# RL6842_IP_SVD register map
Vendor: Realtek
Registers are 32-bit, read-write, reset 0x0 unless marked. A register's access mark holds for its fields unless they carry their own. Offsets are from the block's base; [hi:lo] are bit positions; {n}, {i} and the like mark numbered series; <NAME> marks a mode.

## LP_SYS
Base 0x4100C200
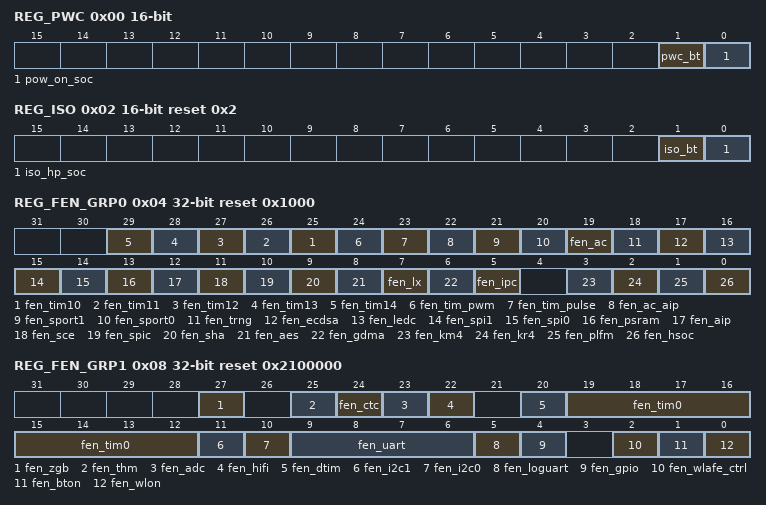
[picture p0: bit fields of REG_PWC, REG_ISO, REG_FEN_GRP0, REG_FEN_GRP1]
0x00 REG_PWC 16-bit
  [1] pwc_bt — This is BT function total power cut control 1: Enable BT power cut 0: Disable
  [0] pow_on_soc — 1:SYS PMC request to enable HP SOC power cut and diable ISO 0: SYS PMC request to disable HP SOC power cut and enable ISO
0x02 REG_ISO 16-bit access per field reset 0x2
  [1] iso_bt rw — 1: isolate signals from PD_LP_BT to other power domain 0: release iso
  [0] iso_hp_soc ro — isolate signals from PD_HP_SOC to other power domain
0x04 REG_FEN_GRP0 reset 0x1000
  [n+15] fen_tim{n} (n=10..14) — 1: enable TIMER {n} function 0: disable
  [24] fen_tim_pwm — 1: enable PWM TIMER function 0: disable
  [23] fen_tim_pulse — 1: enable PULSE TIMER function 0: disable
  [22] fen_ac_aip — 1: enable audio codec analog ip active function, need level shift to 3.3V for audio aip 0: disable
  [21] fen_sport1 — 1: enable SPORT1 function 0: disable
  [20] fen_sport0 — 1: enable SPORT0 function 0: disable
  [19] fen_ac — 1: enable audio codec digital ip active function 0: disable
  [18] fen_trng — 1: enable TRNG function 0: disable
  [17] fen_ecdsa — 1: enable ecdsa function 0: disable
  [16] fen_ledc — 1: enable LEDC function 0: disable
  [15] fen_spi1 — 1: enable SPI1 function 0: disable
  [14] fen_spi0 — 1: enable SPI0 function 0: disable
  [13] fen_psram — 1: enable PSRAM function 0: disable
  [12] fen_aip — AIP control function enable 1: enable 0: disable
  [11] fen_sce — Flash sce function enable 1: enable sce 0: disable
  [10] fen_spic — Flash spic function enable 1: enable flash 0: disable flash
  [9] fen_sha — 1: enable IPSEC SHA function 0: disable
  [8] fen_aes — 1: enable IPSEC AES function 0: disable
  [7] fen_lx — 1: enable LX1 system function 0: disable
  [6] fen_gdma — 1: enable GDMA function 0: disable
  [5] fen_ipc — 1: enable IPC function 0: reset
  [3] fen_km4 — 1: enable KM4 0: reset
  [2] fen_kr4 — 1: enable KR4 0: reset
  [1] fen_plfm — 1: enable platform 0: reset
  [0] fen_hsoc — 1: enable hs soc sytem 0: reset all hs soc sytem , include km4/km0/plfm/hifi
0x08 REG_FEN_GRP1 reset 0x2100000
  [27] fen_zgb — zigbee function enable 1: enable 0: disable
  [25] fen_thm — thermal function enable 1: enable 0: disable
  [24] fen_ctc — captouch function enable 1: enable 0: disable
  [23] fen_adc — lp adc function enable 1: enable 0: disable
  [22] fen_hifi — HIFI core function enable 1: enable 0: disable
  [20] fen_dtim — Debug timer function enable 1: enable 0: disable
  [19:12] fen_tim0 — Basic Timer0-7 function enable 1: enable 0: disable
  [11] fen_i2c1 — I2C1 function enable 1: enable 0: disable
  [10] fen_i2c0 — I2C0 function enable 1: enable 0: disable
  [9:6] fen_uart — Uart function enable (Note uart3 if for BT) 1: enable 0: disable
  [5] fen_loguart — Uartlog function enable 1: enable 0: disable
  [4] fen_gpio — SGPIO function enable 1: enable 0: disable
  [2] fen_wlafe_ctrl — WL RFAFE control function enable 1: enable 0: disable
  [1] fen_bton — BTON function enable 1: enable 0: disable
  [0] fen_wlon — WLON function enable 1: enable 0: disable
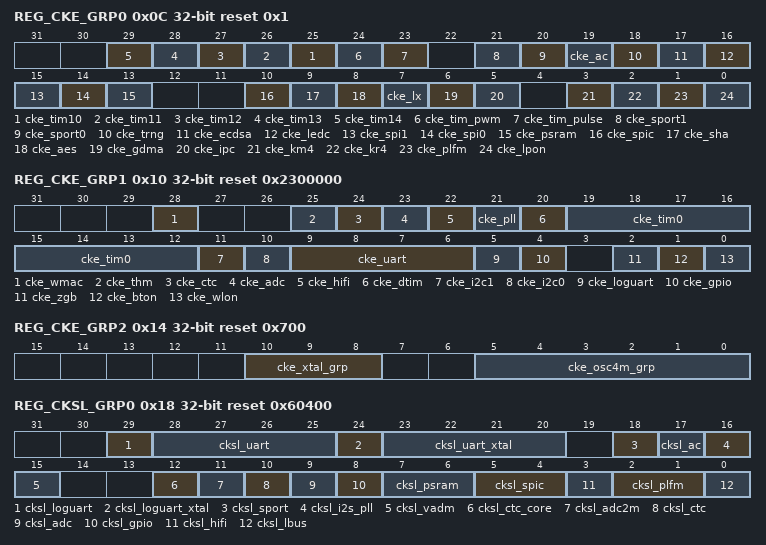
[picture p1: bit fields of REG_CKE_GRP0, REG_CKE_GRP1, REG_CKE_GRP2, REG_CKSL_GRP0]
0x0C REG_CKE_GRP0 reset 0x1
  [n+15] cke_tim{n} (n=10..14) — 1: Enable TIMER {n} clock 0: Disable
  [24] cke_tim_pwm — 1: Enable PWM TIMER clock 0: Disable
  [23] cke_tim_pulse — 1: Enable PULSE TIMER clock 0: Disable
  [21] cke_sport1 — 1: Enable sport1 clock 0: Disable
  [20] cke_sport0 — 1: Enable sport0 clock 0: Disable
  [19] cke_ac — 1: Enable audio codec clock 0: Disable
  [18] cke_trng — 1: Enable trng bus clock 0: Disable
  [17] cke_ecdsa — 1: Enable ecdsa engine clock 0: Disable
  [16] cke_ledc — 1: Enable ledc bus clock 0: Disable
  [15] cke_spi1 — 1: Enable SPI1 clock 0: Disable
  [14] cke_spi0 — 1: Enable SPI0 clock 0: Disable
  [13] cke_psram — 1: Enable PSRAM bus clock 0: Disable
  [10] cke_spic — 1: Enable SPIC source clock
  [9] cke_sha — 1: Enable ipsec SHA clock 0: Disable
  [8] cke_aes — 1: Enable ipsec AES clock 0: Disable
  [7] cke_lx — 1: Enable lx1 bus clock 0: Disable
  [6] cke_gdma — 1: Enable GDMA0 clock 0: Disable
  [5] cke_ipc — 1: Enable IPC clock 0: Disable
  [3] cke_km4 — 1: Enable KM4 clock 0: Disable
  [2] cke_kr4 — 1: Enable KR4 clock 0: Disable
  [1] cke_plfm — 1: Enable platform clock 0: Disable
  [0] cke_lpon — 1.Enable lpon clk 0: Disable Note: this bit is controlled HW PMC, SW shall not modify
0x10 REG_CKE_GRP1 reset 0x2300000
  [28] cke_wmac — 1: Enable WMAC AXI and AHB bus clock 0: Disable
  [25] cke_thm — 1: Enable LS thm clock 0: Disable
  [24] cke_ctc — 1: Enable Captouch clock 0: Disable
  [23] cke_adc — 1: Enable LS ADC clock 0: Disable
  [22] cke_hifi — 1: Enable HIFI core clock 0: Disable
  [21] cke_pll — 1: Enable PLL dividor for KM4/KR4/SRAM 0: Disable when modify KM4/KR4/SRAM dividor param, need set this bit 0 and 1 before switch KM4/KR4/SRAM to PLL from XTAL/OSC4M
  [20] cke_dtim — 1: Enable LS dtim clk 0: Disable
  [19:12] cke_tim0 — LS basic Timer0-7 clk enable 0: Disable
  [11] cke_i2c1 — 1: Enable HS I2C0 clock 0: Disable
  [10] cke_i2c0 — 1: Enable LS I2C clock 0: Disable
  [9:6] cke_uart — 1: Enable Uart clock 0: Disable
  [5] cke_loguart — 1: Enable Uartlog clock 0: Disable
  [4] cke_gpio — 1: Enable GPIO clock 0: Disable
  [2] cke_zgb — 1: enable zigbee clock 0: Disable
  [1] cke_bton — 1: Enable BTON clock 0: Disable
  [0] cke_wlon — 1: Enable WLON clock 0: Disable
0x14 REG_CKE_GRP2 reset 0x700
  [10:8] cke_xtal_grp — XTAL 40M clock used for different use , when neither func used [0]: LP system [1]: 40M peri [2]: 2M peri Note : This field is SW used, HW won't modify
  [5:0] cke_osc4m_grp — OSC4M used for different use , when neither func used , osc4m can be disabled . 0: LP system 4M 1: OSC2M peri 2: WL/BT common 3: WL ana clock 4: BT ana clock 5: RSVD Note : This field is SW used, HW won't modify
0x18 REG_CKSL_GRP0 reset 0x60400
  [29] cksl_loguart — Select loguart trx clock 0: clock is xtal(source is dicided by cksl_loguart_xtal) 1: clock is osc2M
  [28:25] cksl_uart — Select uart rx clock for every uart . cksl_uart[n](n=0,1,2,3) 0: rx clock is xtal(source is dicided by cksl_uart_xtal) 1: rx clock is osc2M
  [24] cksl_loguart_xtal — loguart_xtal clk select 0:clk_xtal_digi 1:clk_xtal_digi_div2
  [23:20] cksl_uart_xtal — uart xtal clk select, cksl_uart_xtal[n](n=0,1,2,3) 0: clk_xtal_digi 1:clk_xtal_digi_div2
  [18] cksl_sport — sport clock selection 0: equal to audio codec main clock (40M) 1: from cpu/dsp pll , after pll selection(cksl_i2s_pll)
  [17] cksl_ac — audio codec main clock selection 0: cpupll divided 40M 1: xtal 40M
  [16] cksl_i2s_pll — source pll slection for sport clk 0: from cpu pll divider output 1: from dsp pll divider output
  [15] cksl_vadm — vad share memory clock select . Note, it must first change this bit to 1,and then shutdown hs plfm . When wakeup , it must first enable hs plfm , finally set this bit to 0 . 0: used by hs plfm clock 1: used by vad buffer ctrol
  [12] cksl_ctc_core — CTC core clock selection 0: 131k 1: xtal2m divider Clock
  [11] cksl_adc2m — lp adc 2m clk selection 0: divider from osc4m 1: divider from xtal
  [10] cksl_ctc — CTC REG clock selection 0: 131k 1: lbus clock
  [9] cksl_adc — ADC INT clock selection 0: lbus clock 1: OSC2M
  [8] cksl_gpio — GPIO INT clock selecton: 0: lbus clock 1: 32.768K clock from SDM
  [7:6] cksl_psram — psram phy clock seleck cksl_psram[0]: 0--source clk is from cpu pll, 1--source clk is from dsp pll cksl_psram[1]: 0--final clk is from cpu/dsp pll divider 1: lbus clk 10/11: from lbus clock 00: from cpu pll divider output 01: from dsp pll divider output
  [5:4] cksl_spic — SPIC clock seleck 10/11: from lbus clock 00: from dsp pll divider output 01: from cpu pll divider output
  [3] cksl_hifi — HIFI core/bus clock seletion 1'b1: lbus clk 1'b0: from dsp pll divider
  [2:1] cksl_plfm — KM4/KR4/HBUS/SRAM clock seletion, they are sync except HBUS 00/01: from lbus clock 10: from cpu pll divider output 11: from dsp pll divider output
  [0] cksl_lbus — lbus clk select 0: osc4m 1:xtal
0x1C REG_CKSL_GRP1
  [3:0] cksl_xtal — xtal selection, Default=40MHz 0000: 40MHz 0001: 25MHz 0010: 13MHz 0011: 19.2MHz 0100: 20MHz 0101: 26MHz 0110: 38.4MHz 0111: 17.664MHz 1000: 16MHz 1001: 14.138MHz 1010: 12MHz 1011: 52MHz 1100: 48MHz 1101: 27MHz 1110: 24MHz 1111: none
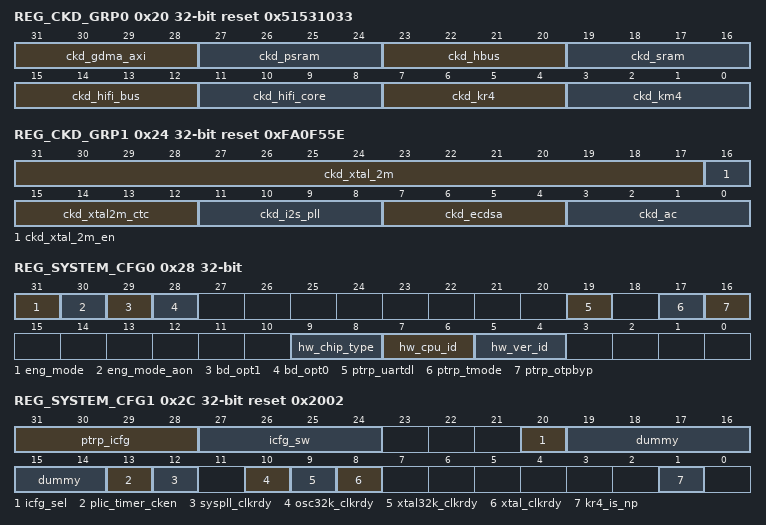
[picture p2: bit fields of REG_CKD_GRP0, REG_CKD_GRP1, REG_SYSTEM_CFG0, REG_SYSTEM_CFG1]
0x20 REG_CKD_GRP0 reset 0x51531033
  [31:28] ckd_gdma_axi — gdma_axi clock divider, it is based on cpu/dsp pll 0~1: not valid 2: div3 3: div4 4: div5 5: div6 other: divider by this value + 1
  [27:24] ckd_psram — psram clock divider, it is based on cpu/dsp pll 0: div1 1: div2 2: div3 3/other: divider by this value + 1
  [23:20] ckd_hbus — hbus clock divider, it is based on cpu/dsp pll 0~1: not valid 2: div3 3: div4 4: div5 other: divider by this value + 1
  [19:16] ckd_sram — sram clock divider, it is based on sys pll 0 : not valid 1: div2 2: div3 3/other: divider by this value + 1
  [15:12] ckd_hifi_bus — HIFI bus clock divider, it is based on ckd_hifi_core 0: div1 1: div2 2: div3 3/other: divider by this value + 1
  [11:8] ckd_hifi_core — HIFI core clock divider, it is based on cpu/dsp pll 0: div1 1: div2 2: div3 3/other: divider by this value + 1
  [7:4] ckd_kr4 — KR4 clock divider, it is based on cpu/dsp pll 0: div1 1: div2 2: div3 3/other: divider by this value + 1
  [3:0] ckd_km4 — KM4 clock divider, it is based on cpu/dsp pll 0: div1 1: div2 2: div3 3/other: divider by this value + 1
0x24 REG_CKD_GRP1 reset 0xFA0F55E
  [31:17] ckd_xtal_2m — Output divided clock frequency for UART: BIT_LSYS_UART_XTAL_DIV_FREQ/1000 (MHz)
  [16] ckd_xtal_2m_en — 1: enable XTAL division circuit for UART
  [15:12] ckd_xtal2m_ctc — xtal 2m divider for captouch core 0: no valid 1: div2 2: div3 3/other: divider by this value + 1
  [11:8] ckd_i2s_pll — is2 pll divider, it is based on cpu/dsp pll output 0~2 : not valid 3: div4 4: div5 other: divider by this value + 1
  [7:4] ckd_ecdsa — ECDSA clock divider, it is based on cpu pll output 0~1: not valid 2: div3 3/other: divider by this value + 1
  [3:0] ckd_ac — audio main clock divider, it is based on cpu pll output 0~6 : not valid 7: div8 8: div9 other: divider by this value + 1
0x28 REG_SYSTEM_CFG0 access per field
  [31] eng_mode ro — Indicate PKG_ENG_SEL pad value 0: normal package; 1: engineering mode
  [30] eng_mode_aon rw — Wrtie 1 to set aon enter eng_mode
  [29] bd_opt1 ro — Bonding option-ext_clk
  [28] bd_opt0 ro — Bonding option-ext_rstb
  [19] ptrp_uartdl ro — Power on trapped uart download value 0: Normal boot 1: uartdownload boot TODO: it may be overwrited by efuse autoload
  [17] ptrp_tmode ro — 0: normal mode 1: test mode
  [16] ptrp_otpbyp ro — 1: force efuse autoload fail
  [9:8] hw_chip_type ro — Chip type 00: ASIC 01: FPGA 10: PALADIUM 11: RTL_SIM
  [7:6] hw_cpu_id ro — Different CPU reading this register will return different value. If read by KR4: return 0 If read by KM4: return 1 if read by HIFI5: return 2
  [5:4] hw_ver_id ro — Vendor ID Download FW version 00: UMC 01: SMIC 10: TSMC
0x2C REG_SYSTEM_CFG1 access per field reset 0x2002
  [31:28] ptrp_icfg ro — Trapped ICFG data value 0: normall mode XXXX: the other mode (Test Mode)
  [27:24] icfg_sw rw — icfg configured by SIC/SW
  [20] icfg_sel rw — If 1, using icfg_sw to replace trapped icfg value.
  [19:14] dummy rw
  [13] plic_timer_cken rw — clock enable of kr4 plic timer
  [12] syspll_clkrdy ro — System pll ready flag 1: ready
  [10] osc32k_clkrdy ro — OSC 128k ready flag 1: ready
  [9] xtal32k_clkrdy ro — XTAL 32k ready flag 1: ready
  [8] xtal_clkrdy ro — XTAL clock stable 1: Clock Stable
  [1] kr4_is_np rw — 1: kr4 is Network Processor, and is the LPS controller 0: km4 is Network Processor, and is the LPS controller
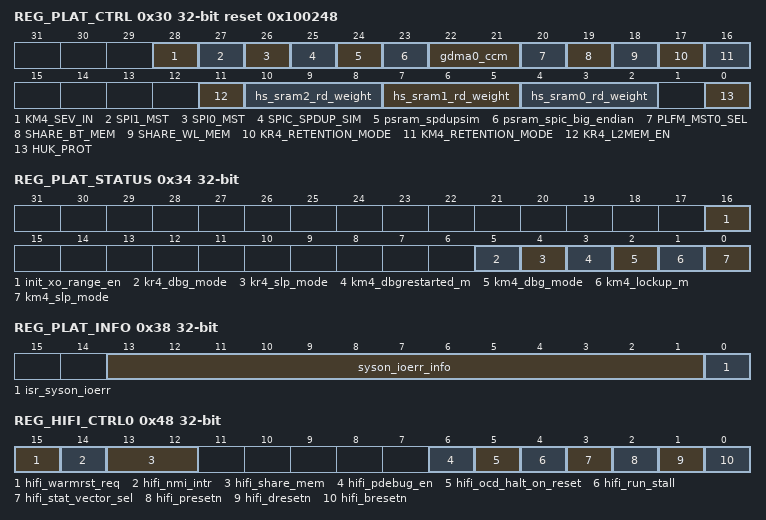
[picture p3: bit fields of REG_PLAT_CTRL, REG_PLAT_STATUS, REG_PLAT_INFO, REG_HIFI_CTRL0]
0x30 REG_PLAT_CTRL access per field reset 0x100248
  [28] KM4_SEV_IN wo — write the bit to 1 will trig sev to km4
  [27] SPI1_MST rw — 1: SPI1 used as master 0: SPI1 used as slaver
  [26] SPI0_MST rw — 1: SPI0 used as master 0: SPI0 used as slaver
  [25] SPIC_SPDUP_SIM rw — 1: SPIC will wait 256 spic_clk cycles before ready 0: SPIC will wait 2^16 spic_clk cycles before ready
  [24] psram_spdupsim rw — psramc simulatin speedup enable
  [23] psram_spic_big_endian rw — 1: big endian 0: little endian
  [22:21] gdma0_ccm rw — GDMA0 clock control mode
  [20] PLFM_MST0_SEL rw — platfrom m0 select 0: KR4 1: OTPC
  [19] SHARE_BT_MEM rw — 1: Enable KM4 to share BT memory
  [18] SHARE_WL_MEM rw — 1: Enable KM4 to share WL memory
  [17] KR4_RETENTION_MODE rw — 1: Enable, when KR4 reset, cache will not be cleared 0: Disable, when KR4 reset, cache will be cleared by HW
  [16] KM4_RETENTION_MODE rw — 1: Enable, when KM4 reset, cache will not be cleared 0: Disable, when KM4 reset, cache will be cleared by HW
  [11] KR4_L2MEM_EN rw — reset value of l2mem enable
  [10:8] hs_sram2_rd_weight rw — Excuted read command number continuously if both read and write command reached
  [7:5] hs_sram1_rd_weight rw — Excuted read command number continuously if both read and write command reached
  [4:2] hs_sram0_rd_weight rw — Excuted read command number continuously if both read and write command reached
  [0] HUK_PROT rw — 0: only cpu can read HUK key 1: no one can read HUK key This bit will be latch to high when it was write to 1 until reset again .
0x34 REG_PLAT_STATUS access per field
  [16] init_xo_range_en rw
  [5] kr4_dbg_mode ro — KR4 debug status
  [4] kr4_slp_mode ro — KR4 sleep status
  [3] km4_dbgrestarted_m ro — KM4 debug restart status
  [2] km4_dbg_mode ro — KM4 halt status
  [1] km4_lockup_m ro — KM4 lockup status
  [0] km4_slp_mode ro — KM4 sleep status
0x38 REG_PLAT_INFO ro
  [13:1] syson_ioerr_info — indicate information of platform master non-secure access the masked syson reg bit2~0: master id, bit12~3: low bit11~2 address of syson reg
  [0] isr_syson_ioerr — indicate error that platform master non-secure access the masked syson reg
0x40 REG_KM4_XO_CTRL0
  [31:0] init_xo_base
0x44 REG_KM4_XO_CTRL1
  [31:0] init_xo_top
0x48 REG_HIFI_CTRL0 access per field
  [15] hifi_warmrst_req rw — hifi warm reset request, high active
  [14] hifi_nmi_intr wo — hifi edge-triggered non-maskable interrupt, one pulse
  [13:12] hifi_share_mem rw — 0:D ram don't share memory to DTCM 1:D ram share 128K memory to DTCM 2:D ram share 256K memory to DTCM, 3 is rsvd
  [6] hifi_pdebug_en rw — traceport debug enable, high active
  [5] hifi_ocd_halt_on_reset rw — on-chip debug mode(OCD) enable, high active
  [4] hifi_run_stall rw — When asserted, stall the processor and shut off much of the clock tree
  [3] hifi_stat_vector_sel rw — When asserted, select External Reset Vector allows the position of the reset
  [2] hifi_presetn rw — APB reset, low active
  [1] hifi_dresetn rw — debug reset,low active
  [0] hifi_bresetn rw — core reset, low active
0x4C REG_HIFI_CTRL1
  [31:0] hifi_alt_reset_vec — External Reset Vector
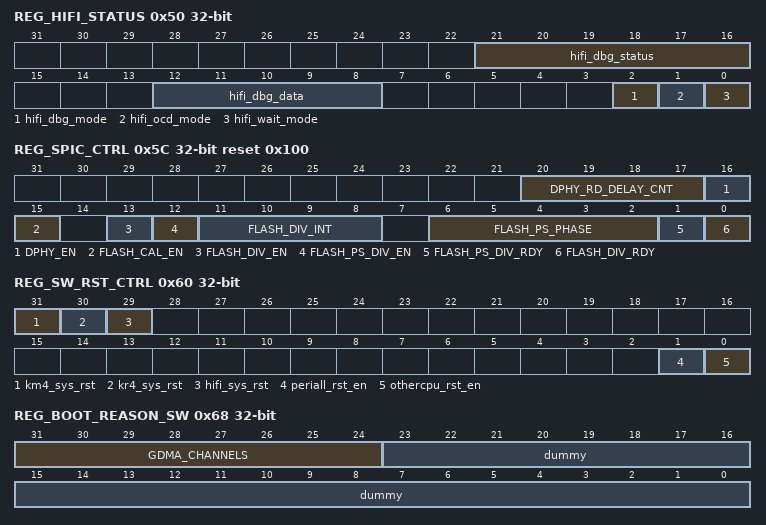
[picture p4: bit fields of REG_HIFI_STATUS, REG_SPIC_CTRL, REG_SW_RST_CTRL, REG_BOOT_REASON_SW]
0x50 REG_HIFI_STATUS ro
  [21:16] hifi_dbg_status — trace port debug status
  [12:8] hifi_dbg_data — trace port debug data
  [2] hifi_dbg_mode — core is on ocd mode but not maskable by SW
  [1] hifi_ocd_mode — core is on ocd mode
  [0] hifi_wait_mode — core is on wait for interrupt mode
0x54 REG_HIFI_DBG_PC ro
  [31:0] hifi_dbg_pc — trace program counter
0x58 REG_HIFI_DBG_INST ro
  [31:0] hifi_dbg_inst — Instruction information
0x5C REG_SPIC_CTRL access per field reset 0x100
  [20:17] DPHY_RD_DELAY_CNT rw — spic_dphy output dealy cnt, when set < 3, output data will occur at fourth or fifth axi clock from the rising edge of spi_rx_data_en; when set >= 3, data will occur after DPHY_RD_DELAY_CNT + 2 axi clock from the rising edge of spi_rx_data_en
  [16] DPHY_EN rw — when set, enable spic_dphy function to read data from flash
  [15] FLASH_CAL_EN rw — Flash calibration enable 1: delay flash sout for calibration 0: bypass flash sout to spic
  [13] FLASH_DIV_EN rw — 1: enable to generate flash clock (no phase shift) divided by 600M pll clock, HW detect this signal's rising edge to start the no phase shift division circuit.
  [12] FLASH_PS_DIV_EN rw — 1: enable to generate flash clock (with phase shift) divided by 600M pll clock, HW detect this signal's rising edge to start the phase shift clock division circuit.
  [11:8] FLASH_DIV_INT rw — Flash clock division ratio, integrate part 0: not support 1: divided by 2 2: divided by 3 3: divided by 4 .. 7: divided by 8 8: divided by 9 9: divided by 10 Note: SPI clock frequency is this divided clock/2
  [6:2] FLASH_PS_PHASE rw — Flash clock phase shift in units of cpu/dsp pll clock cycles. If selected pll is 500MHz, the step is 2ns. 0: shift 0 step 1: shift 1 step ... 19: shift 19 step. Note, this value cannot be set more than FLASH_DIV_INT
  [1] FLASH_PS_DIV_RDY ro — Ready flag of Flash clock with phase shift, Read only (input signal)
  [0] FLASH_DIV_RDY ro — Ready flag of Flash clock, Read only (input signal)
0x60 REG_SW_RST_CTRL
  [31] km4_sys_rst — Only when REG_SW_RST_TRIG is 0x96969696 , this reg can be write
  [30] kr4_sys_rst — Only when REG_SW_RST_TRIG is 0x96969696 , this reg can be write
  [29] hifi_sys_rst — Only when REG_SW_RST_TRIG is 0x96969696 , this reg can be write
  [1] periall_rst_en — 1. warm reset request by one cpu will reset all peri and local cpu 0. warm reset request by one cpu will only reset local cpu Note : peri rst will use sysrst mst also
  [0] othercpu_rst_en — 1. warm reset request by one cpu will reset other cpu's core and local cpu 0. warm reset request by one cpu will only reset local cpu
0x64 REG_SW_RST_TRIG
  [31:0] trig_rst — System reset trigger register Write 0x96969696 to enable the write of reset control Write 0x69696969 will trigger the system if REG_SW_RST_CTRL set .
0x68 REG_BOOT_REASON_SW
  [31:24] GDMA_CHANNELS — Indicate the usage status of every GDMA channel.
  [23:0] dummy
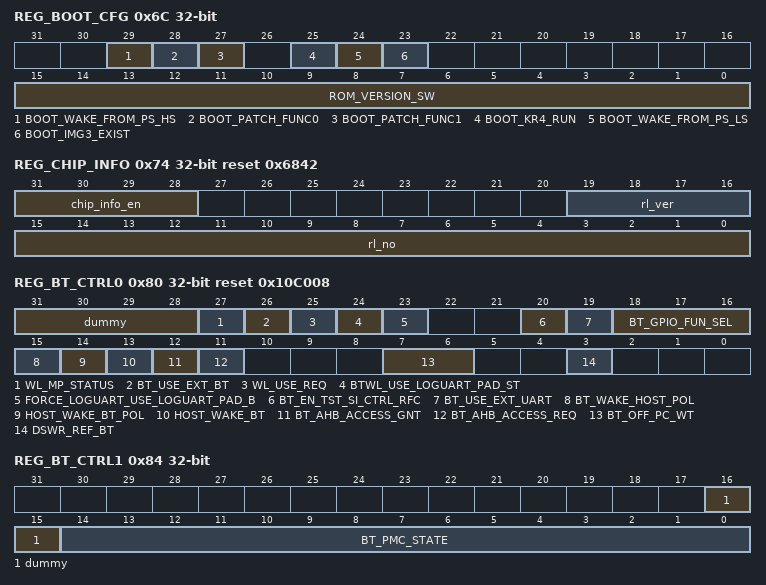
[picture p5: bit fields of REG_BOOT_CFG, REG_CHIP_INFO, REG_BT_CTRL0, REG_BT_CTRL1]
0x6C REG_BOOT_CFG
  [29] BOOT_WAKE_FROM_PS_HS, [28] BOOT_PATCH_FUNC0, [27] BOOT_PATCH_FUNC1, [25] BOOT_KR4_RUN, [24] BOOT_WAKE_FROM_PS_LS, [23] BOOT_IMG3_EXIST, [15:0] ROM_VERSION_SW
0x70 REG_SW_PATCH reset 0x20020000
  [31:0] sw_patch_saddr — SW patch code start addr. OTP physical addr 0x500-0x6FF will autoload to this addr .
0x74 REG_CHIP_INFO access per field reset 0x6842
  [31:28] chip_info_en rw — Enable Internal Chip Information display. 0xA: enable. Others: disable. Note: CHIP_INFO can be read only if CHIP_INFO_EN[3:0]=0xA, otherwise the read result will return 0x0.
  [19:16] rl_ver ro — CHIP cut verison : 0: A-cut 1: B-cut ...
  [15:0] rl_no ro — CHIP RL NUMBER : 0x6842
0x80 REG_BT_CTRL0 access per field reset 0x10C008
  [31:28] dummy rw — HW used only , these are for reserved.
  [27] WL_MP_STATUS rw — Wi-Fi MP status
  [26] BT_USE_EXT_BT rw — 1: select external BT 0: select internal BT
  [25] WL_USE_REQ rw — who uses loguart trx pad depends on the xor of WL_USE_REQ and BT_USE_REQ, wifi can send use request by change the value of WL_USE_REQ
  [24] BTWL_USE_LOGUART_PAD_ST ro — The state of xor of WL_USE_REQ and BT_USE_REQ. 0: loguart use loguart trx pad 1: bt hci use loguart trx pad
  [23] FORCE_LOGUART_USE_LOGUART_PAD_B rw — Force wifi soc to use loguart pad mandatory if necessary 0: loguart use loguart trx pad 1: who uses loguart trx pad depends on BTWL_USE_LOGUART_PAD_ST
  [20] BT_EN_TST_SI_CTRL_RFC rw — 进入Test Mode 8,9 , 且同時 BT_EN_TST_SI_CTRL_RFC=1 , 才將RFC 端的SI 3 wire交由專線BT_SI_*_TST 控制; 若I2C 想要access RFC,设置BT_EN_TST_SI_CTRL_RFC=0 或者 將BT_SI_ENB_TST pull high(如果BT_SI_ENB_TST 有出 PIN)
  [19] BT_USE_EXT_UART rw — 1: BT use external uart 0: BT use internal uart
  [18:16] BT_GPIO_FUN_SEL rw — BT GPIO function select, 5:I2C mode
  [15] BT_WAKE_HOST_POL rw — 1:BT_WAKE_HOST to CPU and pinmux 0:pinmux to CPU for external trig
  [14] HOST_WAKE_BT_POL rw — 1:HOST_WAKE_BT to BT and pinmux 0:pinmux to BT for external trig
  [13] HOST_WAKE_BT rw — CPU set this bit to 1 to wake BT
  [12] BT_AHB_ACCESS_GNT ro — access grant for system master access BT reg through AHB bus
  [11] BT_AHB_ACCESS_REQ rw — system master set this bit to 1 and wait BT_AHB_ACCESS_GNT=1 before access BT reg through AHB bus, when access finish, shall set this bit to 0
  [7:6] BT_OFF_PC_WT rw — 云
  [3] DSWR_REF_BT rw — core swr parameter refer BT status
0x84 REG_BT_CTRL1 access per field
  [16:15] dummy rw — HW used only , these are for reserved.
  [14:0] BT_PMC_STATE ro — indicate bt_misc PMC current state, for debug
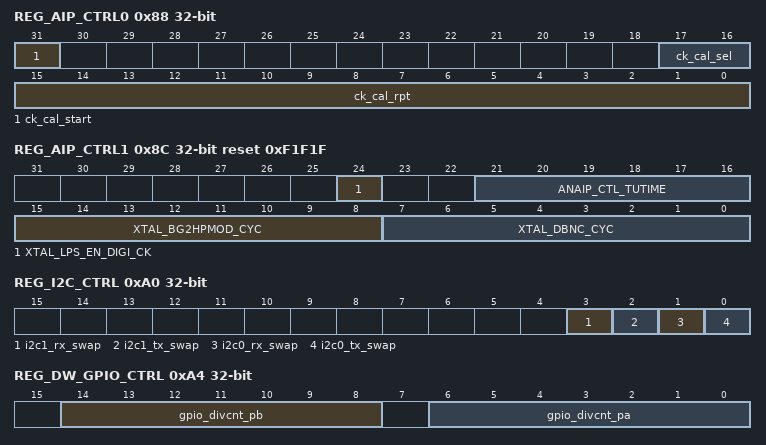
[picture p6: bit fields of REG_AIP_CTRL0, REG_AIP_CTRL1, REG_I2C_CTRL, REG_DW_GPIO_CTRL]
0x88 REG_AIP_CTRL0 access per field
  [31] ck_cal_start rw — Start clk calibration . This bit will auto-set to 0 when cal done .
  [17:16] ck_cal_sel rw — Calibration clock selection . The refrence clock is xtal clock. 0: OSC4M 1: AON100K 2: AON128K for SDM
  [15:0] ck_cal_rpt ro — Clock calibration result
0x8C REG_AIP_CTRL1 reset 0xF1F1F
  [24] XTAL_LPS_EN_DIGI_CK — 0: disable XTAL clock for digital when XTAL enter LPS mode 1: enable XTAL clock for digital when XTAL enter LPS mode
  [21:16] ANAIP_CTL_TUTIME — Timeunit of SWR/XTAL arbitration circuit, in unit of ANA4M, Default time unit: 4us
  [15:8] XTAL_BG2HPMOD_CYC — The time interval between BG enable to XTAL switch to HP Mode, the timeunit is control by 0x13C[21:16]: BIT_LSYS_ANAIP_CTL_TUTIME
  [7:0] XTAL_DBNC_CYC — De-bounce time of XTAL enable request from WIFI & SYSON PMC, the timeunit is control by 0x13C[21:16]: BIT_LSYS_ANAIP_CTL_TUTIME
0xA0 REG_I2C_CTRL
  [3] i2c1_rx_swap — I2C1 RX swap control
  [2] i2c1_tx_swap — I2C1 TX swap control
  [1] i2c0_rx_swap — I2C0 RX swap control
  [0] i2c0_tx_swap — I2C0 TX swap control
0xA4 REG_DW_GPIO_CTRL
  [14:8] gpio_divcnt_pb — divider for dw gpiob debounce clk
  [6:0] gpio_divcnt_pa — divider for dw gpioa debounce clk
0xA8 REG_LXBUS_DBG0 ro
  [31:0] timeout_addr_mst — lx sys bus addr debug out
0xAC REG_LXBUS_DBG1 ro
  [31:0] timeout_addr_slv — lx sys bus addr debug out
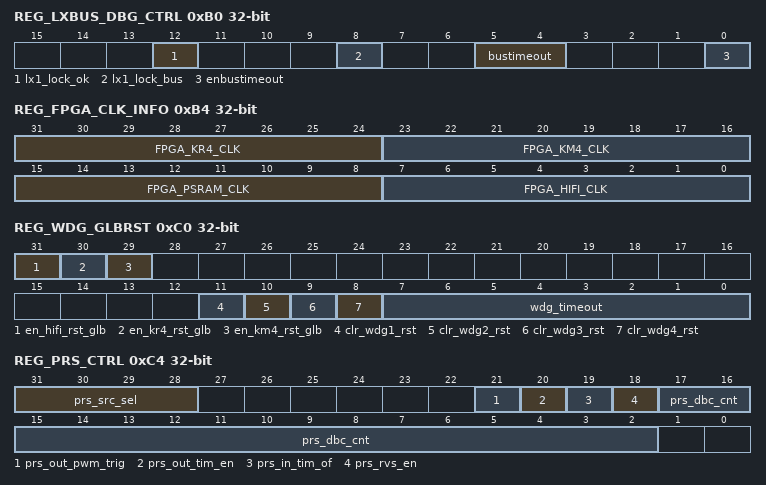
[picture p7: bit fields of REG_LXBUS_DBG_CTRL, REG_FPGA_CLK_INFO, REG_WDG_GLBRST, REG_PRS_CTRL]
0xB0 REG_LXBUS_DBG_CTRL access per field
  [12] lx1_lock_ok ro — lock lx1 bus lock ok
  [8] lx1_lock_bus rw — lock lx1 bus for debug
  [5:4] bustimeout rw — lx sys bus arb timeout thresh
  [0] enbustimeout rw — lx sys bus arb timeout enable
0xB4 REG_FPGA_CLK_INFO ro
  [31:24] FPGA_KR4_CLK — FPGA KR4 clock
  [23:16] FPGA_KM4_CLK — FPGA KM4 clock
  [15:8] FPGA_PSRAM_CLK — FPGA PSRAM clock
  [7:0] FPGA_HIFI_CLK — FPGA HIFI clock
0xB8 REG_FLASH_PARA_ADDR
  [31:0] dummy
0xBC SCAN_CTRL
  [31:16] dummy — HW used only , these are for reserved.
0xC0 REG_WDG_GLBRST access per field
  [31] en_hifi_rst_glb rw — 1: if wdg of hifi assert wdg_reset, will trigger global reset directly. Follow the smart. 0: the wdg_reset of hifi wdg reset itself firstly, the global reset occurs only caused by timeout
  [30] en_kr4_rst_glb rw — 1: if wdg of hifi assert wdg_reset, will trigger global reset directly. Follow the smart. 0: the wdg_reset of hifi wdg reset itself firstly, if the kr4 is np, the global reset occurs only caused by timeout
  [29] en_km4_rst_glb rw — 1: if wdg of hifi assert wdg_reset, will trigger global reset directly. Follow the smart. 0: the wdg_reset of hifi wdg reset itself firstly, if the km4 is np, the global reset occurs only caused by timeout
  [11] clr_wdg1_rst wo — write 1 to clear the km4_s_wdg_rst, glb_wdg_rst is not included
  [10] clr_wdg2_rst wo — write 1 to clear the km4_ns_wdg_rst, glb_wdg_rst is not included
  [9] clr_wdg3_rst wo — write 1 to clear the kr4_wdg_rst, glb_wdg_rst is not included
  [8] clr_wdg4_rst wo — write 1 to clear the dsp_wdg_rst, glb_wdg_rst is not included
  [7:0] wdg_timeout rw — threshold of wdg timer, if wdg_timer >= wdg_timeout, will trigger global reset. Unit is 10us 0 means not support
0xC4 REG_PRS_CTRL
  [31:28] prs_src_sel — PRS trigger source select: 000: none 001: gpio trigger 010: comparator output 011: audio zcd_0 100: audio zcd_1 101: audio zcd_2
  [21] prs_out_pwm_trig — enable for output trigger to pwm
  [20] prs_out_tim_en — enable for output en signal to basic timer
  [19] prs_in_tim_of — enable for basic timer overflow input
  [18] prs_rvs_en — invert polarity for PRS input, 0: posedge polarity 1: negedge polarity
  [17:2] prs_dbc_cnt — debounce count for PRS funciton
0xCC REG_DUMMY_089
  [31:0] dummy — HW used only , these are for reserved.
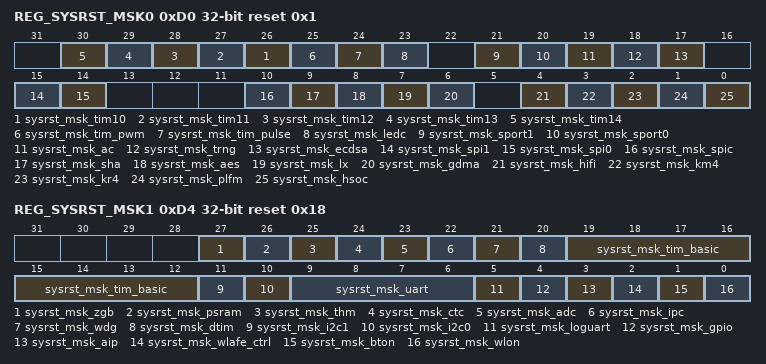
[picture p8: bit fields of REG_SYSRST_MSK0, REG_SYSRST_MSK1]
0xD0 REG_SYSRST_MSK0 reset 0x1
  [n+16] sysrst_msk_tim{n} (n=10..14) — 1: mask HP TIMER{n} reset when sys reset happen 0: disable
  [25] sysrst_msk_tim_pwm — 1: mask HP TIMER_PWM reset when sys reset happen 0: disable
  [24] sysrst_msk_tim_pulse — 1: mask HP TIMER_PULSE reset when sys reset happen 0: disable
  [23] sysrst_msk_ledc — 1: mask LEDC reset when sys reset happen 0: disable
  [21] sysrst_msk_sport1 — 1: mask SPORT1 reset when sys reset happen 0: disable
  [20] sysrst_msk_sport0 — 1: mask SPORT0 reset when sys reset happen 0: disable
  [19] sysrst_msk_ac — 1: mask audio codec active reset when sys reset happen 0: disable
  [18] sysrst_msk_trng — 1: mask TRNG reset when sys reset happen 0: disable
  [17] sysrst_msk_ecdsa — 1: mask ecdsa reset when sys reset happen 0: disable
  [15] sysrst_msk_spi1 — 1: mask SPI1 reset when sys reset happen 0: disable
  [14] sysrst_msk_spi0 — 1: mask SPI0 reset when sys reset happen 0: disable
  [10] sysrst_msk_spic — mask Flash spic reset when sys reset happen mask 1: mask flash 0: disable flash
  [9] sysrst_msk_sha — 1: mask IPSEC SHA reset when sys reset happen 0: disable
  [8] sysrst_msk_aes — 1: mask IPSEC AES reset when sys reset happen 0: disable
  [7] sysrst_msk_lx — 1: mask LX reset when sys reset happen 0: disable
  [6] sysrst_msk_gdma — 1: mask GDMA reset when sys reset happen 0: disable
  [4] sysrst_msk_hifi — 1: mask DSP (HIFI5) reset when sys reset happen 0: reset
  [3] sysrst_msk_km4 — 1: mask KM4 reset when sys reset happen 0: reset
  [2] sysrst_msk_kr4 — 1: mask KR4 reset when sys reset happen 0: reset
  [1] sysrst_msk_plfm — 1: mask platform 0: reset
  [0] sysrst_msk_hsoc — 1: mask HP_SOC system reset when sys reset happen 0: reset
0xD4 REG_SYSRST_MSK1 reset 0x18
  [27] sysrst_msk_zgb — 1: mask zgb reset when sys reset happen 0: disable Note: for zgb is in wlan off domain , after turn wlan off , it need an 0->1 transiton
  [26] sysrst_msk_psram — 1: mask PSRAM reset when sys reset happen 0: disable
  [25] sysrst_msk_thm — mask thml reset when sys reset happen mask
  [24] sysrst_msk_ctc — 1: mask Captouch ADC reset when sys reset happen 0: reset
  [23] sysrst_msk_adc — 1: mask LS ADC reset when sys reset happen 0: reset
  [22] sysrst_msk_ipc — 1: mask IPC reset when sys reset happen 0: reset
  [21] sysrst_msk_wdg — 1: mask LS WDG 1~4 reset when sys reset happen 0: reset
  [20] sysrst_msk_dtim — 1: mask LP dtim reset when sys reset happen mask 0: reset
  [19:12] sysrst_msk_tim_basic — 1: mask LP basic TIMER0-7 reset when sys reset happen 0: disable
  [11] sysrst_msk_i2c1 — 1: mask HS I2C1 reset when sys reset happen 0: reset
  [10] sysrst_msk_i2c0 — 1: mask LS I2C0 reset when sys reset happen 0: reset
  [9:6] sysrst_msk_uart — 1: mask UART reset when sys reset happen 0: disable
  [5] sysrst_msk_loguart — 1: mask LOGUART reset when sys reset happen 0: disable
  [4] sysrst_msk_gpio — 1: mask LS GPIO reset when sys reset happen 0: reset
  [3] sysrst_msk_aip — 1: mask aip reset when sys reset happen mask 0: reset
  [2] sysrst_msk_wlafe_ctrl — 1: mask WL RFAFE control circuit, shall be 1 when mask WL or BT use WL RFAFE 0: reset
  [1] sysrst_msk_bton — mask BTON reset when sys reset happen 1: mask 0: disable
  [0] sysrst_msk_wlon — mask WLON reset when sys reset happen mask 1: mask 0: disable
0xF0 REG_BOUNDARY_CHK reset 0xBDC10512
  [31:0] dummy — HW used only , Used for access boundary check, SYSON is 512B which is 000-1FF.
0xF4 REG_DUMMY_090
  [31:0] dummy — HW used only , these are for reserved.
0xF8 REG_DUMMY_AIP_CTRL1 reset 0xFFFF
  [31:0] aip_ctrl_rsvd1 — reserved for aip control
0xFC REG_DUMMY_AIP_INFO1 ro
  [31:0] aip_info_rsvd1 — reserved for aip info indication
